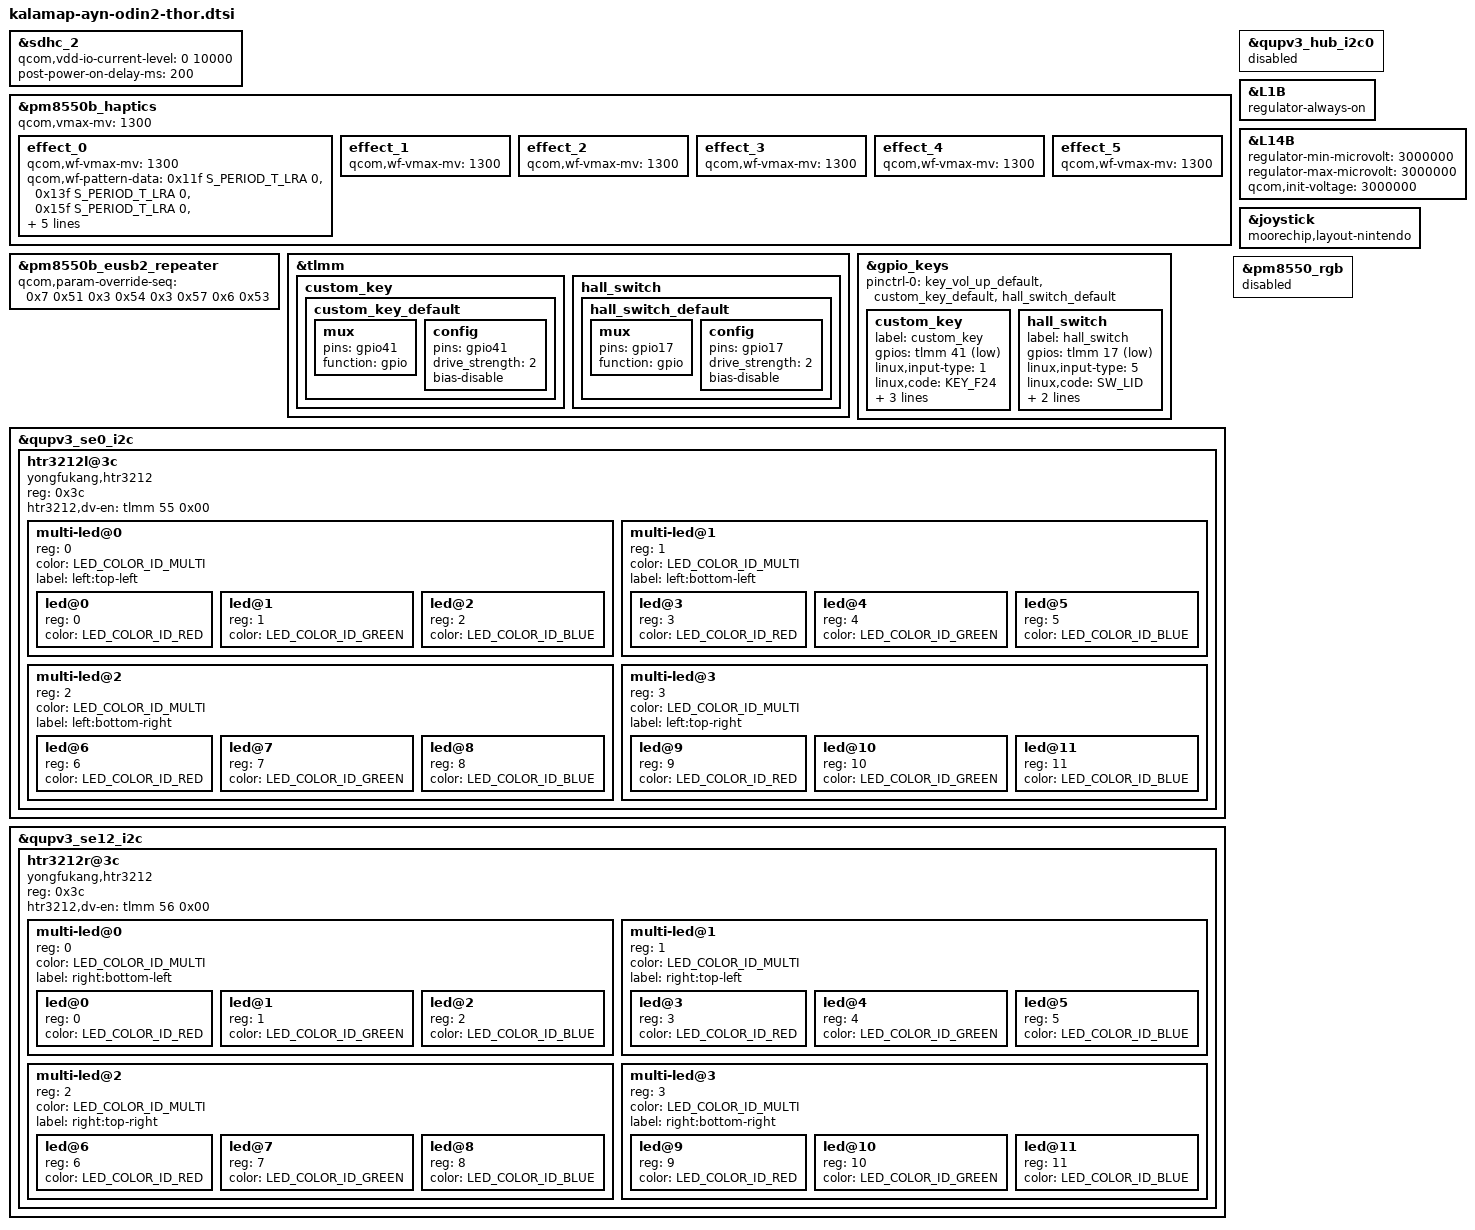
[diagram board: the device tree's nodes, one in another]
#include "kalamap-moorechip-common.dtsi"
#include <dt-bindings/leds/common.h>

&sdhc_2 {
	qcom,vdd-io-current-level = <0 10000>;
	post-power-on-delay-ms = <200>;
};

&pm8550b_haptics {
	qcom,vmax-mv = <1300>;

	effect_0 {
		/* CLICK */
		qcom,wf-vmax-mv = <1300>;
		qcom,wf-pattern-data =  <0x11f  S_PERIOD_T_LRA  0>,
					<0x13f  S_PERIOD_T_LRA  0>,
					<0x15f  S_PERIOD_T_LRA  0>,
					<0x17f  S_PERIOD_T_LRA  0>,
					<0x17f  S_PERIOD_T_LRA  0>,
					<0x15f  S_PERIOD_T_LRA  0>,
					<0x13f  S_PERIOD_T_LRA  0>,
					<0x11f  S_PERIOD_T_LRA  0>;
		/delete-property/ qcom,wf-pattern-preload;
	};

	effect_1 {
		/* DOUBLE_CLICK */
		qcom,wf-vmax-mv = <1300>;
	};

	effect_2 {
		/* TICK */
		qcom,wf-vmax-mv = <1300>;
	};

	effect_3 {
		/* THUD */
		qcom,wf-vmax-mv = <1300>;
	};

	effect_4 {
		/* POP */
		qcom,wf-vmax-mv = <1300>;
	};

	effect_5 {
		/* HEAVY CLICK */
		qcom,wf-vmax-mv = <1300>;
	};
};

&pm8550b_eusb2_repeater {
	qcom,param-override-seq =
		/* <value reg_offset> */
		/* Adjust HS trasmit amplitude */
		<0x7 0x51
		/* Squelch detection threshold */
		 0x3 0x54
		/* Tx pre-emphasis tuning */
		 0x3 0x57
		/* HS disconnect threshold */
		 0x6 0x53>;
};

&tlmm {
	custom_key: custom_key {
		custom_key_default: custom_key_default {
			mux {
				pins = "gpio41";
				function = "gpio";
			};
			config {
				pins = "gpio41";
				drive_strength = <2>;
				bias-disable;
			};
		};
	};

	hall_switch: hall_switch {
		hall_switch_default: hall_switch_default {
			mux {
				pins = "gpio17";
				function = "gpio";
			};
			config {
				pins = "gpio17";
				drive_strength = <2>;
				bias-disable;
			};
		};
	};
};

&gpio_keys {
	pinctrl-0 = <&key_vol_up_default>, <&custom_key_default>, <&hall_switch_default>;

	custom_key {
		label = "custom_key";
		gpios = <&tlmm 41 GPIO_ACTIVE_LOW>;
		linux,input-type = <1>;
		linux,code = <KEY_F24>;
		gpio-key,wakeup;
		debounce-interval = <15>;
		linux,can-disable;
	};

	hall_switch {
		label = "hall_switch";
		gpios = <&tlmm 17 GPIO_ACTIVE_LOW>;
		linux,input-type = <5>;
		linux,code = <SW_LID>;
		gpio-key,wakeup;
		linux,can-disable;
	};
};

&qupv3_hub_i2c0 {
	status = "disabled";
};

&qupv3_se0_i2c {
	#address-cells = <1>;
	#size-cells = <0>;
	status = "ok";

	htr3212l@3c {
		compatible = "yongfukang,htr3212";
		reg = <0x3c>;
		htr3212,dv-en = <&tlmm 55 0x00>;

		multi-led@0 {
			#address-cells = <1>;
			#size-cells = <0>;
			reg = <0>;
			color = <LED_COLOR_ID_MULTI>;
			label = "left:top-left";

			led@0 {
				reg = <0>;
				color = <LED_COLOR_ID_RED>;
			};

			led@1 {
				reg = <1>;
				color = <LED_COLOR_ID_GREEN>;
			};

			led@2 {
				reg = <2>;
				color = <LED_COLOR_ID_BLUE>;
			};
		};

		multi-led@1 {
			#address-cells = <1>;
			#size-cells = <0>;
			reg = <1>;
			color = <LED_COLOR_ID_MULTI>;
			label = "left:bottom-left";

			led@3 {
				reg = <3>;
				color = <LED_COLOR_ID_RED>;
			};

			led@4 {
				reg = <4>;
				color = <LED_COLOR_ID_GREEN>;
			};

			led@5 {
				reg = <5>;
				color = <LED_COLOR_ID_BLUE>;
			};
		};

		multi-led@2 {
			#address-cells = <1>;
			#size-cells = <0>;
			reg = <2>;
			color = <LED_COLOR_ID_MULTI>;
			label = "left:bottom-right";

			led@6 {
				reg = <6>;
				color = <LED_COLOR_ID_RED>;
			};

			led@7 {
				reg = <7>;
				color = <LED_COLOR_ID_GREEN>;
			};

			led@8 {
				reg = <8>;
				color = <LED_COLOR_ID_BLUE>;
			};
		};

		multi-led@3 {
			#address-cells = <1>;
			#size-cells = <0>;
			reg = <3>;
			color = <LED_COLOR_ID_MULTI>;
			label = "left:top-right";

			led@9 {
				reg = <9>;
				color = <LED_COLOR_ID_RED>;
			};

			led@10 {
				reg = <10>;
				color = <LED_COLOR_ID_GREEN>;
			};

			led@11 {
				reg = <11>;
				color = <LED_COLOR_ID_BLUE>;
			};
		};
	};
};

&qupv3_se12_i2c {
	#address-cells = <1>;
	#size-cells = <0>;
	status = "ok";

	htr3212r@3c {
		compatible = "yongfukang,htr3212";
		reg = <0x3c>;
		htr3212,dv-en = <&tlmm 56 0x00>;

		multi-led@0 {
			#address-cells = <1>;
			#size-cells = <0>;
			reg = <0>;
			color = <LED_COLOR_ID_MULTI>;
			label = "right:bottom-left";

			led@0 {
				reg = <0>;
				color = <LED_COLOR_ID_RED>;
			};

			led@1 {
				reg = <1>;
				color = <LED_COLOR_ID_GREEN>;
			};

			led@2 {
				reg = <2>;
				color = <LED_COLOR_ID_BLUE>;
			};
		};

		multi-led@1 {
			#address-cells = <1>;
			#size-cells = <0>;
			reg = <1>;
			color = <LED_COLOR_ID_MULTI>;
			label = "right:top-left";

			led@3 {
				reg = <3>;
				color = <LED_COLOR_ID_RED>;
			};

			led@4 {
				reg = <4>;
				color = <LED_COLOR_ID_GREEN>;
			};

			led@5 {
				reg = <5>;
				color = <LED_COLOR_ID_BLUE>;
			};
		};

		multi-led@2 {
			#address-cells = <1>;
			#size-cells = <0>;
			reg = <2>;
			color = <LED_COLOR_ID_MULTI>;
			label = "right:top-right";

			led@6 {
				reg = <6>;
				color = <LED_COLOR_ID_RED>;
			};

			led@7 {
				reg = <7>;
				color = <LED_COLOR_ID_GREEN>;
			};

			led@8 {
				reg = <8>;
				color = <LED_COLOR_ID_BLUE>;
			};
		};

		multi-led@3 {
			#address-cells = <1>;
			#size-cells = <0>;
			reg = <3>;
			color = <LED_COLOR_ID_MULTI>;
			label = "right:bottom-right";

			led@9 {
				reg = <9>;
				color = <LED_COLOR_ID_RED>;
			};

			led@10 {
				reg = <10>;
				color = <LED_COLOR_ID_GREEN>;
			};

			led@11 {
				reg = <11>;
				color = <LED_COLOR_ID_BLUE>;
			};
		};
	};
};

// TODO: ???
&L1B {
	regulator-always-on;
};

&L14B {
	regulator-min-microvolt = <3000000>;
	regulator-max-microvolt = <3000000>;
	qcom,init-voltage = <3000000>;
};

&joystick {
	moorechip,layout-nintendo;
};

&pm8550_rgb {
	status = "disabled";
};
